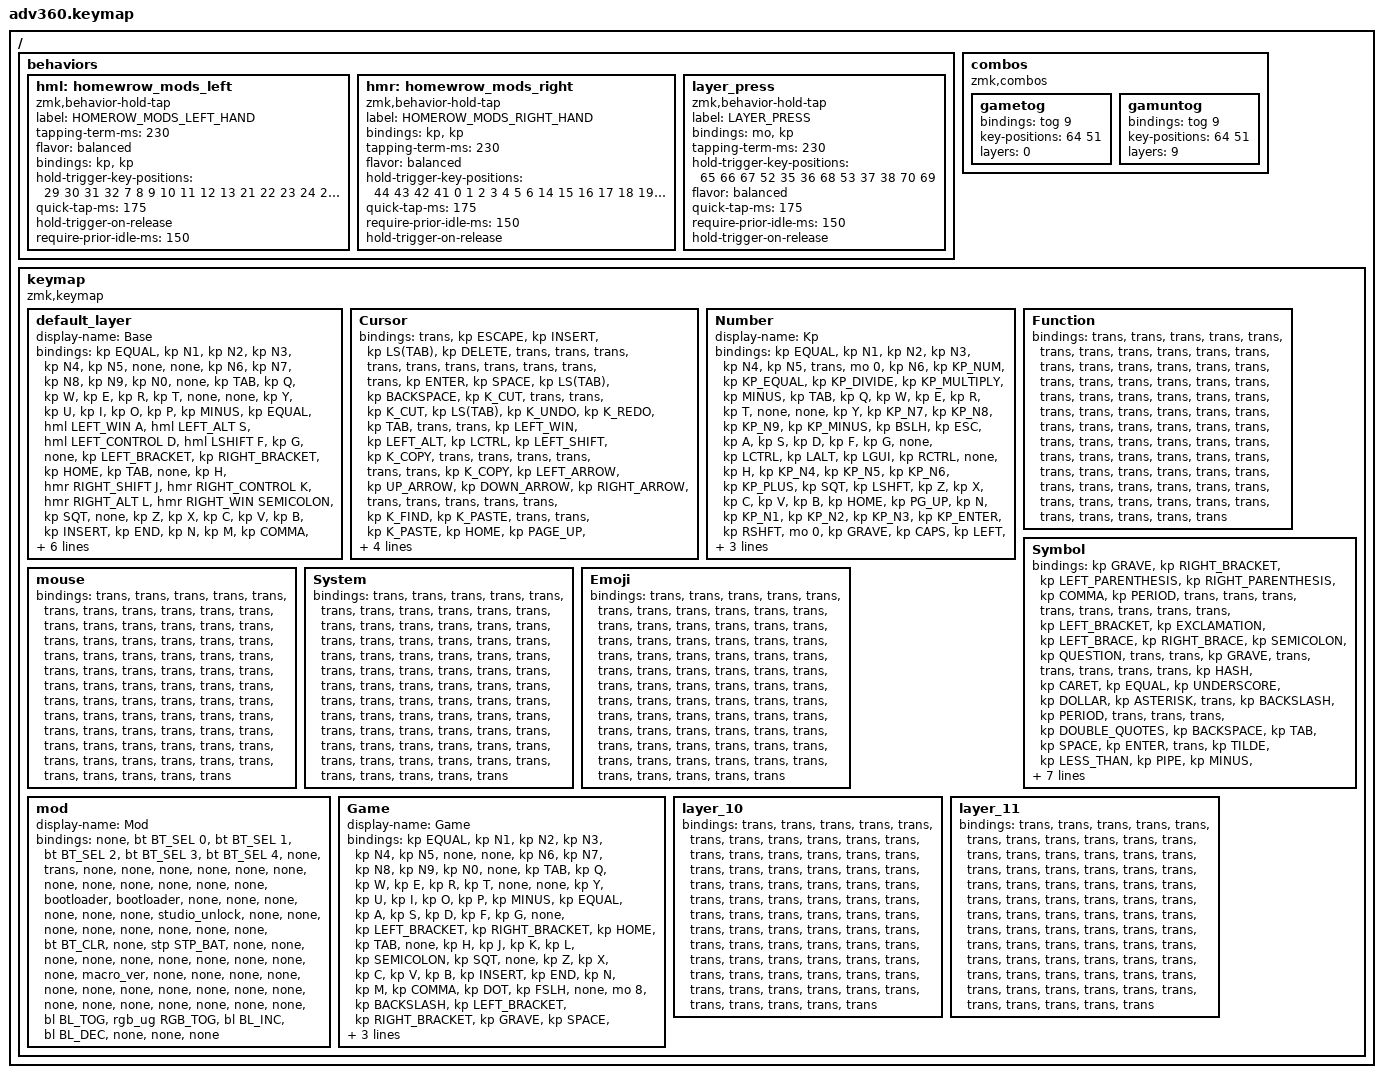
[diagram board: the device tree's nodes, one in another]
#include <dt-bindings/zmk/stp.h>
#include <behaviors.dtsi>
#include <dt-bindings/zmk/backlight.h>
#include <dt-bindings/zmk/bt.h>
#include <dt-bindings/zmk/keys.h>
#include <dt-bindings/zmk/rgb.h>

/ {
    behaviors {
        #include "macros.dtsi"
      #include "version.dtsi"

        hml: homewrow_mods_left {
            compatible = "zmk,behavior-hold-tap";
            label = "HOMEROW_MODS_LEFT_HAND";
            #binding-cells = <2>;
            tapping-term-ms = <230>;
            flavor = "balanced";
            bindings = <&kp>, <&kp>;

            hold-trigger-key-positions = <29 30 31 32 7 8 9 10 11 12 13 21 22 23 24 25 26 27 37 38 39 40 41 42 43 44 45 53 54 55 56 57 58 59 68 69 70 71 72 73 74 75>;
            quick-tap-ms = <175>;
            hold-trigger-on-release;
            require-prior-idle-ms = <150>;
        };

        hmr: homewrow_mods_right {
            compatible = "zmk,behavior-hold-tap";
            label = "HOMEROW_MODS_RIGHT_HAND";
            bindings = <&kp>, <&kp>;

            #binding-cells = <2>;
            tapping-term-ms = <230>;
            flavor = "balanced";
            hold-trigger-key-positions = <44 43 42 41 0 1 2 3 4 5 6 14 15 16 17 18 19 20 28 29 30 31 32 33 34 35 36 46 47 48 49 50 51 52 60 61 62 63 64 65 66 67>;
            quick-tap-ms = <175>;
            require-prior-idle-ms = <150>;
            hold-trigger-on-release;
        };

        layer_press: layer_press {
            compatible = "zmk,behavior-hold-tap";
            label = "LAYER_PRESS";
            bindings = <&mo>, <&kp>;

            #binding-cells = <2>;
            tapping-term-ms = <230>;
            hold-trigger-key-positions = <65 66 67 52 35 36 68 53 37 38 70 69>;
            flavor = "balanced";
            quick-tap-ms = <175>;
            require-prior-idle-ms = <150>;
            hold-trigger-on-release;
        };
    };

    combos {
        compatible = "zmk,combos";

        gametog {
            bindings = <&tog 9>;
            key-positions = <64 51>;
            layers = <0>;
        };

        gamuntog {
            bindings = <&tog 9>;
            key-positions = <64 51>;
            layers = <9>;
        };
    };

    keymap {
        compatible = "zmk,keymap";

        default_layer {
            display-name = "Base";
            bindings = <
&kp EQUAL  &kp N1           &kp N2            &kp N3               &kp N4         &kp N5  &none                                                                                   &none                 &kp N6  &kp N7              &kp N8                &kp N9             &kp N0                    &none
&kp TAB    &kp Q            &kp W             &kp E                &kp R          &kp T   &none                                                                                   &none                 &kp Y   &kp U               &kp I                 &kp O              &kp P                     &kp MINUS
&kp EQUAL  &hml LEFT_WIN A  &hml LEFT_ALT S   &hml LEFT_CONTROL D  &hml LSHIFT F  &kp G   &none                     &kp LEFT_BRACKET  &kp RIGHT_BRACKET      &kp HOME  &kp TAB    &none                 &kp H   &hmr RIGHT_SHIFT J  &hmr RIGHT_CONTROL K  &hmr RIGHT_ALT L   &hmr RIGHT_WIN SEMICOLON  &kp SQT
&none      &kp Z            &kp X             &kp C                &kp V          &kp B                                               &kp INSERT             &kp END                                    &kp N   &kp M               &kp COMMA             &kp DOT            &kp FSLH                  &none
&mo 8      &kp BACKSLASH    &kp LEFT_BRACKET  &kp RIGHT_BRACKET    &kp GRAVE              &layer_press 1 BACKSPACE  &kp DEL           &kp ESC                &none     &kp ENTER  &layer_press 4 SPACE          &kp PAGE_UP         &kp K_SCROLL_UP       &kp K_SCROLL_DOWN  &kp PAGE_DOWN             &mo 8
            >;
        };

        Cursor {
            bindings = <
&trans  &kp ESCAPE    &kp INSERT    &kp LS(TAB)  &kp DELETE      &trans       &trans                                      &trans  &trans       &trans          &trans        &trans          &trans           &trans
&trans  &kp ENTER     &kp SPACE     &kp LS(TAB)  &kp BACKSPACE   &kp K_CUT    &trans                                      &trans  &kp K_CUT    &kp LS(TAB)     &kp K_UNDO    &kp K_REDO      &kp TAB          &trans
&trans  &kp LEFT_WIN  &kp LEFT_ALT  &kp LCTRL    &kp LEFT_SHIFT  &kp K_COPY   &trans  &trans  &trans      &trans  &trans  &trans  &kp K_COPY   &kp LEFT_ARROW  &kp UP_ARROW  &kp DOWN_ARROW  &kp RIGHT_ARROW  &trans
&trans  &trans        &trans        &trans       &kp K_FIND      &kp K_PASTE                  &trans      &trans                  &kp K_PASTE  &kp HOME        &kp PAGE_UP   &kp PAGE_DOWN   &kp END          &trans
&trans  &kp K_UNDO    &kp K_REDO    &trans       &trans                       &trans  &trans  &trans      &trans  &trans  &trans               &kp K_FIND      &trans        &trans          &trans           &trans
            >;
        };

        Number {
            display-name = "Kp";
            bindings = <
&kp EQUAL  &kp N1     &kp N2    &kp N3    &kp N4     &kp N5  &trans                                                               &mo 0      &kp N6  &kp KP_NUM  &kp KP_EQUAL  &kp KP_DIVIDE  &kp KP_MULTIPLY  &kp MINUS
&kp TAB    &kp Q      &kp W     &kp E     &kp R      &kp T   &none                                                                &none      &kp Y   &kp KP_N7   &kp KP_N8     &kp KP_N9      &kp KP_MINUS     &kp BSLH
&kp ESC    &kp A      &kp S     &kp D     &kp F      &kp G   &none     &kp LCTRL              &kp LALT      &kp LGUI   &kp RCTRL  &none      &kp H   &kp KP_N4   &kp KP_N5     &kp KP_N6      &kp KP_PLUS      &kp SQT
&kp LSHFT  &kp Z      &kp X     &kp C     &kp V      &kp B                                    &kp HOME      &kp PG_UP                        &kp N   &kp KP_N1   &kp KP_N2     &kp KP_N3      &kp KP_ENTER     &kp RSHFT
&mo 0      &kp GRAVE  &kp CAPS  &kp LEFT  &kp RIGHT          &kp BSPC  &layer_press 2 DELETE  &kp END       &kp PG_DN  &kp ENTER  &kp KP_N0          &kp UP      &kp DOWN      &kp KP_DOT     &kp RBKT         &mo 0
            >;
        };

        Function {
            bindings = <
&trans  &trans  &trans  &trans  &trans  &trans  &trans                                      &trans  &trans  &trans  &trans  &trans  &trans  &trans
&trans  &trans  &trans  &trans  &trans  &trans  &trans                                      &trans  &trans  &trans  &trans  &trans  &trans  &trans
&trans  &trans  &trans  &trans  &trans  &trans  &trans  &trans  &trans      &trans  &trans  &trans  &trans  &trans  &trans  &trans  &trans  &trans
&trans  &trans  &trans  &trans  &trans  &trans                  &trans      &trans                  &trans  &trans  &trans  &trans  &trans  &trans
&trans  &trans  &trans  &trans  &trans          &trans  &trans  &trans      &trans  &trans  &trans          &trans  &trans  &trans  &trans  &trans
            >;
        };

        Symbol {
            bindings = <
&kp GRAVE         &kp RIGHT_BRACKET  &kp LEFT_PARENTHESIS  &kp RIGHT_PARENTHESIS  &kp COMMA         &kp PERIOD    &trans                                                        &trans  &trans             &trans         &trans       &trans      &trans      &trans
&kp LEFT_BRACKET  &kp EXCLAMATION    &kp LEFT_BRACE        &kp RIGHT_BRACE        &kp SEMICOLON     &kp QUESTION  &trans                                                        &trans  &kp GRAVE          &trans         &trans       &trans      &trans      &trans
&kp HASH          &kp CARET          &kp EQUAL             &kp UNDERSCORE         &kp DOLLAR        &kp ASTERISK  &trans       &kp BACKSLASH  &kp PERIOD        &trans  &trans  &trans  &kp DOUBLE_QUOTES  &kp BACKSPACE  &kp TAB      &kp SPACE   &kp ENTER   &trans
&kp TILDE         &kp LESS_THAN      &kp PIPE              &kp MINUS              &kp GREATER_THAN  &kp SLASH                                 &kp ASTERISK      &trans                  &kp SQT            &kp DELETE     &kp LS(TAB)  &kp INSERT  &kp ESCAPE  &trans
&trans            &kp AMPERSAND      &kp SQT               &kp DOUBLE_QUOTES      &kp PLUS                        &kp PERCENT  &kp COLON      &kp AT_SIGN       &trans  &trans  &trans                     &trans         &trans       &trans      &trans      &trans
            >;
        };

        mouse {
            bindings = <
&trans  &trans  &trans  &trans  &trans  &trans  &trans                                      &trans  &trans  &trans  &trans  &trans  &trans  &trans
&trans  &trans  &trans  &trans  &trans  &trans  &trans                                      &trans  &trans  &trans  &trans  &trans  &trans  &trans
&trans  &trans  &trans  &trans  &trans  &trans  &trans  &trans  &trans      &trans  &trans  &trans  &trans  &trans  &trans  &trans  &trans  &trans
&trans  &trans  &trans  &trans  &trans  &trans                  &trans      &trans                  &trans  &trans  &trans  &trans  &trans  &trans
&trans  &trans  &trans  &trans  &trans          &trans  &trans  &trans      &trans  &trans  &trans          &trans  &trans  &trans  &trans  &trans
            >;
        };

        System {
            bindings = <
&trans  &trans  &trans  &trans  &trans  &trans  &trans                                      &trans  &trans  &trans  &trans  &trans  &trans  &trans
&trans  &trans  &trans  &trans  &trans  &trans  &trans                                      &trans  &trans  &trans  &trans  &trans  &trans  &trans
&trans  &trans  &trans  &trans  &trans  &trans  &trans  &trans  &trans      &trans  &trans  &trans  &trans  &trans  &trans  &trans  &trans  &trans
&trans  &trans  &trans  &trans  &trans  &trans                  &trans      &trans                  &trans  &trans  &trans  &trans  &trans  &trans
&trans  &trans  &trans  &trans  &trans          &trans  &trans  &trans      &trans  &trans  &trans          &trans  &trans  &trans  &trans  &trans
            >;
        };

        Emoji {
            bindings = <
&trans  &trans  &trans  &trans  &trans  &trans  &trans                                      &trans  &trans  &trans  &trans  &trans  &trans  &trans
&trans  &trans  &trans  &trans  &trans  &trans  &trans                                      &trans  &trans  &trans  &trans  &trans  &trans  &trans
&trans  &trans  &trans  &trans  &trans  &trans  &trans  &trans  &trans      &trans  &trans  &trans  &trans  &trans  &trans  &trans  &trans  &trans
&trans  &trans  &trans  &trans  &trans  &trans                  &trans      &trans                  &trans  &trans  &trans  &trans  &trans  &trans
&trans  &trans  &trans  &trans  &trans          &trans  &trans  &trans      &trans  &trans  &trans          &trans  &trans  &trans  &trans  &trans
            >;
        };

        mod {
            display-name = "Mod";
            bindings = <
&none           &bt BT_SEL 0  &bt BT_SEL 1  &bt BT_SEL 2  &bt BT_SEL 3  &bt BT_SEL 4  &none                                                  &trans           &none  &none       &none       &none  &none  &none
&none           &none         &none         &none         &none         &none         &bootloader                                            &bootloader      &none  &none       &none       &none  &none  &none
&studio_unlock  &none         &none         &none         &none         &none         &none        &none  &none      &bt BT_CLR  &none       &stp STP_BAT     &none  &none       &none       &none  &none  &none
&none           &none         &none         &none         &macro_ver    &none                             &none      &none                                    &none  &none       &none       &none  &none  &none
&none           &none         &none         &none         &none                       &none        &none  &none      &none       &bl BL_TOG  &rgb_ug RGB_TOG         &bl BL_INC  &bl BL_DEC  &none  &none  &none
            >;
        };

        Game {
            display-name = "Game";
            bindings = <
&kp EQUAL  &kp N1         &kp N2            &kp N3             &kp N4     &kp N5  &none                                                                    &none          &kp N6  &kp N7       &kp N8           &kp N9             &kp N0         &none
&kp TAB    &kp Q          &kp W             &kp E              &kp R      &kp T   &none                                                                    &none          &kp Y   &kp U        &kp I            &kp O              &kp P          &kp MINUS
&kp EQUAL  &kp A          &kp S             &kp D              &kp F      &kp G   &none      &kp LEFT_BRACKET  &kp RIGHT_BRACKET      &kp HOME  &kp TAB    &none          &kp H   &kp J        &kp K            &kp L              &kp SEMICOLON  &kp SQT
&none      &kp Z          &kp X             &kp C              &kp V      &kp B                                &kp INSERT             &kp END                             &kp N   &kp M        &kp COMMA        &kp DOT            &kp FSLH       &none
&mo 8      &kp BACKSLASH  &kp LEFT_BRACKET  &kp RIGHT_BRACKET  &kp GRAVE          &kp SPACE  &kp LEFT_SHIFT    &kp ESC                &none     &kp ENTER  &kp BACKSPACE          &kp PAGE_UP  &kp K_SCROLL_UP  &kp K_SCROLL_DOWN  &kp PAGE_DOWN  &mo 8
            >;
        };

        layer_10 {
            bindings = <
&trans  &trans  &trans  &trans  &trans  &trans  &trans                                      &trans  &trans  &trans  &trans  &trans  &trans  &trans
&trans  &trans  &trans  &trans  &trans  &trans  &trans                                      &trans  &trans  &trans  &trans  &trans  &trans  &trans
&trans  &trans  &trans  &trans  &trans  &trans  &trans  &trans  &trans      &trans  &trans  &trans  &trans  &trans  &trans  &trans  &trans  &trans
&trans  &trans  &trans  &trans  &trans  &trans                  &trans      &trans                  &trans  &trans  &trans  &trans  &trans  &trans
&trans  &trans  &trans  &trans  &trans          &trans  &trans  &trans      &trans  &trans  &trans          &trans  &trans  &trans  &trans  &trans
            >;
        };

        layer_11 {
            bindings = <
&trans  &trans  &trans  &trans  &trans  &trans  &trans                                      &trans  &trans  &trans  &trans  &trans  &trans  &trans
&trans  &trans  &trans  &trans  &trans  &trans  &trans                                      &trans  &trans  &trans  &trans  &trans  &trans  &trans
&trans  &trans  &trans  &trans  &trans  &trans  &trans  &trans  &trans      &trans  &trans  &trans  &trans  &trans  &trans  &trans  &trans  &trans
&trans  &trans  &trans  &trans  &trans  &trans                  &trans      &trans                  &trans  &trans  &trans  &trans  &trans  &trans
&trans  &trans  &trans  &trans  &trans          &trans  &trans  &trans      &trans  &trans  &trans          &trans  &trans  &trans  &trans  &trans
            >;
        };
    };
};
